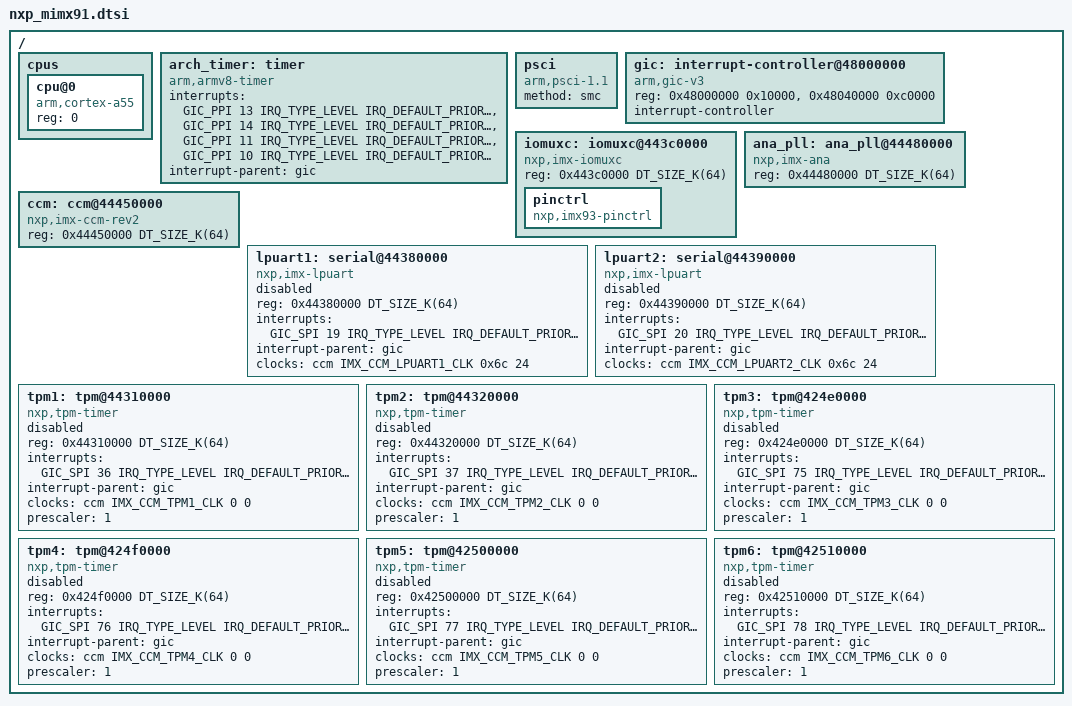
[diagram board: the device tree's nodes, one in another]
/*
 * Copyright 2025 NXP
 *
 * SPDX-License-Identifier: Apache-2.0
 */

#include <mem.h>
#include <freq.h>
#include <arm64/armv8-a.dtsi>
#include <zephyr/dt-bindings/clock/imx_ccm_rev2.h>
#include <zephyr/dt-bindings/interrupt-controller/arm-gic.h>

/ {
	#address-cells = <1>;
	#size-cells = <1>;

	cpus {
		#address-cells = <1>;
		#size-cells = <0>;

		cpu@0 {
			device_type = "cpu";
			compatible = "arm,cortex-a55";
			reg = <0>;
		};
	};

	arch_timer: timer {
		compatible = "arm,armv8-timer";
		interrupts = <GIC_PPI 13 IRQ_TYPE_LEVEL
			      IRQ_DEFAULT_PRIORITY>,
			     <GIC_PPI 14 IRQ_TYPE_LEVEL
			      IRQ_DEFAULT_PRIORITY>,
			     <GIC_PPI 11 IRQ_TYPE_LEVEL
			      IRQ_DEFAULT_PRIORITY>,
			     <GIC_PPI 10 IRQ_TYPE_LEVEL
			      IRQ_DEFAULT_PRIORITY>;
		interrupt-parent = <&gic>;
	};

	psci: psci {
		compatible = "arm,psci-1.1";
		method = "smc";
	};

	gic: interrupt-controller@48000000 {
		compatible = "arm,gic-v3", "arm,gic";
		reg = <0x48000000 0x10000>, /* GIC Dist */
		      <0x48040000 0xc0000>; /* GICR (RD_base + SGI_base) */
		interrupt-controller;
		#interrupt-cells = <4>;
		status = "okay";
	};

	iomuxc: iomuxc@443c0000 {
		compatible = "nxp,imx-iomuxc";
		reg = <0x443c0000 DT_SIZE_K(64)>;
		status = "okay";
		pinctrl: pinctrl {
			status = "okay";
			compatible = "nxp,imx93-pinctrl";
		};
	};

	ana_pll: ana_pll@44480000 {
		compatible = "nxp,imx-ana";
		reg = <0x44480000 DT_SIZE_K(64)>;
	};

	ccm: ccm@44450000 {
		compatible = "nxp,imx-ccm-rev2";
		reg = <0x44450000 DT_SIZE_K(64)>;
		#clock-cells = <3>;
	};

	lpuart1: serial@44380000 {
		compatible = "nxp,imx-lpuart", "nxp,lpuart";
		reg = <0x44380000 DT_SIZE_K(64)>;
		interrupts = <GIC_SPI 19 IRQ_TYPE_LEVEL IRQ_DEFAULT_PRIORITY>;
		interrupt-names = "irq_0";
		interrupt-parent = <&gic>;
		clocks = <&ccm IMX_CCM_LPUART1_CLK 0x6c 24>;
		status = "disabled";
	};

	lpuart2: serial@44390000 {
		compatible = "nxp,imx-lpuart", "nxp,lpuart";
		reg = <0x44390000 DT_SIZE_K(64)>;
		interrupts = <GIC_SPI 20 IRQ_TYPE_LEVEL IRQ_DEFAULT_PRIORITY>;
		interrupt-names = "irq_0";
		interrupt-parent = <&gic>;
		clocks = <&ccm IMX_CCM_LPUART2_CLK 0x6c 24>;
		status = "disabled";
	};

	tpm1: tpm@44310000 {
		compatible = "nxp,tpm-timer";
		reg = <0x44310000 DT_SIZE_K(64)>;
		interrupts = <GIC_SPI 36 IRQ_TYPE_LEVEL IRQ_DEFAULT_PRIORITY>;
		interrupt-names = "irq_0";
		interrupt-parent = <&gic>;
		clocks = <&ccm IMX_CCM_TPM1_CLK 0 0>;
		prescaler = <1>;
		status = "disabled";
	};

	tpm2: tpm@44320000 {
		compatible = "nxp,tpm-timer";
		reg = <0x44320000 DT_SIZE_K(64)>;
		interrupts = <GIC_SPI 37 IRQ_TYPE_LEVEL IRQ_DEFAULT_PRIORITY>;
		interrupt-names = "irq_0";
		interrupt-parent = <&gic>;
		clocks = <&ccm IMX_CCM_TPM2_CLK 0 0>;
		prescaler = <1>;
		status = "disabled";
	};

	tpm3: tpm@424e0000 {
		compatible = "nxp,tpm-timer";
		reg = <0x424e0000 DT_SIZE_K(64)>;
		interrupts = <GIC_SPI 75 IRQ_TYPE_LEVEL IRQ_DEFAULT_PRIORITY>;
		interrupt-names = "irq_0";
		interrupt-parent = <&gic>;
		clocks = <&ccm IMX_CCM_TPM3_CLK 0 0>;
		prescaler = <1>;
		status = "disabled";
	};

	tpm4: tpm@424f0000 {
		compatible = "nxp,tpm-timer";
		reg = <0x424f0000 DT_SIZE_K(64)>;
		interrupts = <GIC_SPI 76 IRQ_TYPE_LEVEL IRQ_DEFAULT_PRIORITY>;
		interrupt-names = "irq_0";
		interrupt-parent = <&gic>;
		clocks = <&ccm IMX_CCM_TPM4_CLK 0 0>;
		prescaler = <1>;
		status = "disabled";
	};

	tpm5: tpm@42500000 {
		compatible = "nxp,tpm-timer";
		reg = <0x42500000 DT_SIZE_K(64)>;
		interrupts = <GIC_SPI 77 IRQ_TYPE_LEVEL IRQ_DEFAULT_PRIORITY>;
		interrupt-names = "irq_0";
		interrupt-parent = <&gic>;
		clocks = <&ccm IMX_CCM_TPM5_CLK 0 0>;
		prescaler = <1>;
		status = "disabled";
	};

	tpm6: tpm@42510000 {
		compatible = "nxp,tpm-timer";
		reg = <0x42510000 DT_SIZE_K(64)>;
		interrupts = <GIC_SPI 78 IRQ_TYPE_LEVEL IRQ_DEFAULT_PRIORITY>;
		interrupt-names = "irq_0";
		interrupt-parent = <&gic>;
		clocks = <&ccm IMX_CCM_TPM6_CLK 0 0>;
		prescaler = <1>;
		status = "disabled";
	};
};
